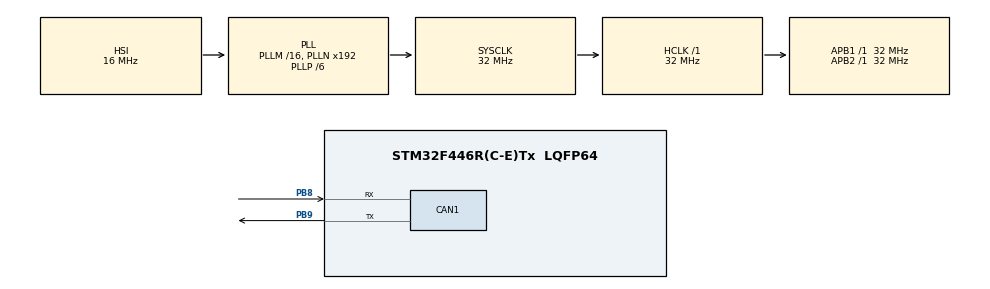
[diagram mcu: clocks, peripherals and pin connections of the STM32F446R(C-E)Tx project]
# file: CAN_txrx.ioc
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CAN1.CalculateTimeQuantum=500.0
Mcu.Family=STM32F4
Mcu.Name=STM32F446R(C-E)Tx
Mcu.Package=LQFP64
NVIC.PriorityGroup=NVIC_PRIORITYGROUP_4
PB8.Mode=Master
PB8.Signal=CAN1_RX
PB9.Mode=Master
PB9.Signal=CAN1_TX
ProjectManager.HeapSize=0x200
ProjectManager.StackSize=0x400
ProjectManager.TargetToolchain=SW4STM32
RCC.AHBFreq_Value=32000000
RCC.APB1Freq_Value=32000000
RCC.APB1TimFreq_Value=32000000
RCC.APB2Freq_Value=32000000
RCC.APB2TimFreq_Value=32000000
RCC.CortexFreq_Value=32000000
RCC.HCLKFreq_Value=32000000
RCC.PLLP=RCC_PLLP_DIV6
RCC.SYSCLKFreq_VALUE=32000000
RCC.SYSCLKSource=RCC_SYSCLKSOURCE_PLLCLK
RCC.USBFreq_Value=96000000
RCC.VCOOutputFreq_Value=192000000
board=custom

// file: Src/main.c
/* USER CODE BEGIN Header */
/**
  ******************************************************************************
  * @file           : main.c
  * @brief          : Main program body
  ******************************************************************************
  * @attention
  *
  * <h2><center>&copy; Copyright (c) 2019 STMicroelectronics.
  * All rights reserved.</center></h2>
  *
  * This software component is licensed by ST under BSD 3-Clause license,
  * the "License"; You may not use this file except in compliance with the
  * License. You may obtain a copy of the License at:
  *                        opensource.org/licenses/BSD-3-Clause
  *
  ******************************************************************************
  */
/* USER CODE END Header */

#include "main.h"

CAN_HandleTypeDef hcan1;
CAN_FilterTypeDef sFilterConfig1;
CAN_TxHeaderTypeDef pHeader1;

void SystemClock_Config(void);
static void MX_GPIO_Init(void);
static void MX_CAN1_Init(void);

/* USER CODE BEGIN 0 */
unsigned char tx[8];
unsigned char rx[8];
/* USER CODE END 0 */

int main(void)
{

  /* MCU Configuration--------------------------------------------------------*/

  /* Reset of all peripherals, Initializes the Flash interface and the Systick. */
  HAL_Init();

  /* Configure the system clock */
  SystemClock_Config();

  /* Initialize all configured peripherals */
  MX_GPIO_Init();
  MX_CAN1_Init();
  /* USER CODE BEGIN 2 */
  if(HAL_CAN_Start(&hcan1) != HAL_OK)
  {
  	Error_Handler();
  };
  /* USER CODE END 2 */

  /* Infinite loop */
  while (1)
  {
	pHeader1.StdId = 0x0321;
	pHeader1.ExtId = 0x0321;
	pHeader1.DLC = 2;
	tx[0] = 25;
	tx[1] = 21;
	if (HAL_CAN_AddTxMessage(&hcan1, &pHeader1, tx[8], 10) != HAL_OK)
	{
	  Error_Handler();
	}

	if(HAL_CAN_GetRxMessage(&hcan1, CAN_RX_FIFO0, &pHeader1, rx[8]) != HAL_OK)
	{
	  Error_Handler();
	}

  }
}

void SystemClock_Config(void)
{
  RCC_OscInitTypeDef RCC_OscInitStruct = {0};
  RCC_ClkInitTypeDef RCC_ClkInitStruct = {0};

  /** Configure the main internal regulator output voltage
  */
  __HAL_RCC_PWR_CLK_ENABLE();
  __HAL_PWR_VOLTAGESCALING_CONFIG(PWR_REGULATOR_VOLTAGE_SCALE3);
  /** Initializes the CPU, AHB and APB busses clocks
  */
  RCC_OscInitStruct.OscillatorType = RCC_OSCILLATORTYPE_HSI;
  RCC_OscInitStruct.HSIState = RCC_HSI_ON;
  RCC_OscInitStruct.HSICalibrationValue = RCC_HSICALIBRATION_DEFAULT;
  RCC_OscInitStruct.PLL.PLLState = RCC_PLL_ON;
  RCC_OscInitStruct.PLL.PLLSource = RCC_PLLSOURCE_HSI;
  RCC_OscInitStruct.PLL.PLLM = 16;
  RCC_OscInitStruct.PLL.PLLN = 192;
  RCC_OscInitStruct.PLL.PLLP = RCC_PLLP_DIV6;
  RCC_OscInitStruct.PLL.PLLQ = 2;
  RCC_OscInitStruct.PLL.PLLR = 2;
  if (HAL_RCC_OscConfig(&RCC_OscInitStruct) != HAL_OK)
  {
    Error_Handler();
  }
  /** Initializes the CPU, AHB and APB busses clocks
  */
  RCC_ClkInitStruct.ClockType = RCC_CLOCKTYPE_HCLK|RCC_CLOCKTYPE_SYSCLK
                              |RCC_CLOCKTYPE_PCLK1|RCC_CLOCKTYPE_PCLK2;
  RCC_ClkInitStruct.SYSCLKSource = RCC_SYSCLKSOURCE_PLLCLK;
  RCC_ClkInitStruct.AHBCLKDivider = RCC_SYSCLK_DIV1;
  RCC_ClkInitStruct.APB1CLKDivider = RCC_HCLK_DIV1;
  RCC_ClkInitStruct.APB2CLKDivider = RCC_HCLK_DIV1;

  if (HAL_RCC_ClockConfig(&RCC_ClkInitStruct, FLASH_LATENCY_1) != HAL_OK)
  {
    Error_Handler();
  }
}

static void MX_CAN1_Init(void)
{

  hcan1.Instance = CAN1;
  hcan1.Init.Prescaler = 16;
  hcan1.Init.Mode = CAN_MODE_NORMAL;
  hcan1.Init.SyncJumpWidth = CAN_SJW_1TQ;
  hcan1.Init.TimeSeg1 = CAN_BS1_1TQ;
  hcan1.Init.TimeSeg2 = CAN_BS2_1TQ;
  hcan1.Init.TimeTriggeredMode = DISABLE;
  hcan1.Init.AutoBusOff = DISABLE;
  hcan1.Init.AutoWakeUp = DISABLE;
  hcan1.Init.AutoRetransmission = DISABLE;
  hcan1.Init.ReceiveFifoLocked = DISABLE;
  hcan1.Init.TransmitFifoPriority = DISABLE;
  if (HAL_CAN_Init(&hcan1) != HAL_OK)
  {
    Error_Handler();
  }
  /* USER CODE BEGIN CAN1_Init 2 */

  sFilterConfig1.FilterIdHigh = 0x0000;
  sFilterConfig1.FilterIdLow = 0x0000;
  sFilterConfig1.FilterMaskIdHigh = 0x0000;
  sFilterConfig1.FilterMaskIdLow = 0x0000;
  sFilterConfig1.FilterMode = CAN_FILTERMODE_IDMASK;
  sFilterConfig1.FilterScale = CAN_FILTERSCALE_32BIT;
  sFilterConfig1.FilterFIFOAssignment = 0;
  sFilterConfig1.FilterActivation = ENABLE;
  if (HAL_CAN_ConfigFilter(&hcan1, &sFilterConfig1) != HAL_OK)
    {
      /* Filter configuration Error */
      Error_Handler();
    }
  pHeader1.IDE = CAN_ID_STD;
  pHeader1.RTR = CAN_RTR_DATA;
  /* USER CODE END CAN1_Init 2 */

}

static void MX_GPIO_Init(void)
{

  /* GPIO Ports Clock Enable */
  __HAL_RCC_GPIOB_CLK_ENABLE();

}

void Error_Handler(void)
{
}

/************************ (C) COPYRIGHT STMicroelectronics *****END OF FILE****/
